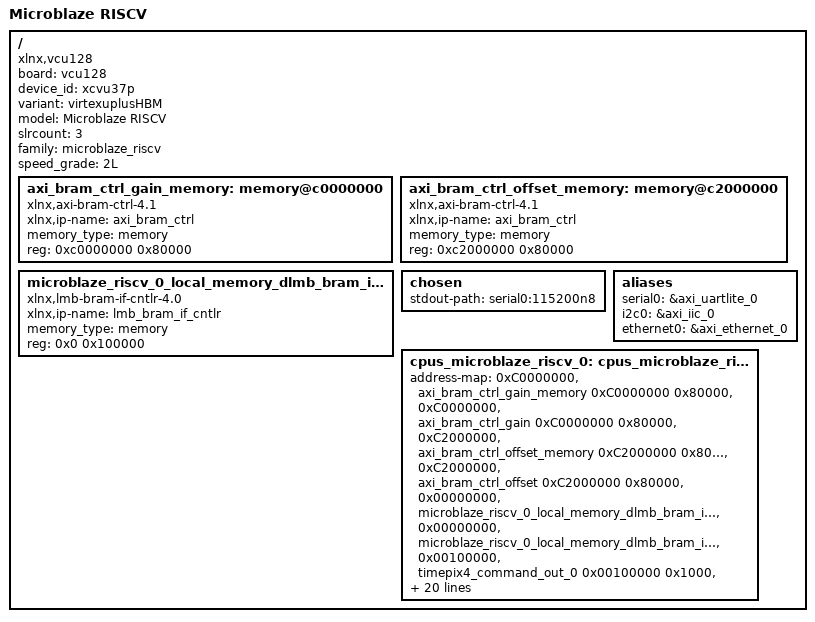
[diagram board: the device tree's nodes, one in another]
/dts-v1/;
#include "pl.dtsi"
/ {
	board = "vcu128";
	compatible = "xlnx,vcu128";
	device_id = "xcvu37p";
	#address-cells = <1>;
	variant = "virtexuplusHBM";
	model = "Microblaze RISCV";
	#size-cells = <1>;
	slrcount = <3>;
	family = "microblaze_riscv";
	speed_grade = "2L";
	axi_bram_ctrl_gain_memory: memory@c0000000 {
		compatible = "xlnx,axi-bram-ctrl-4.1";
		xlnx,ip-name = "axi_bram_ctrl";
		device_type = "memory";
		memory_type = "memory";
		reg = <0xc0000000 0x80000>;
	};
	axi_bram_ctrl_offset_memory: memory@c2000000 {
		compatible = "xlnx,axi-bram-ctrl-4.1";
		xlnx,ip-name = "axi_bram_ctrl";
		device_type = "memory";
		memory_type = "memory";
		reg = <0xc2000000 0x80000>;
	};
	microblaze_riscv_0_local_memory_dlmb_bram_if_cntlr_memory: memory@0 {
		compatible = "xlnx,lmb-bram-if-cntlr-4.0";
		xlnx,ip-name = "lmb_bram_if_cntlr";
		device_type = "memory";
		memory_type = "memory";
		reg = <0x0 0x100000>;
	};
	chosen {
		stdout-path = "serial0:115200n8";
	};
	aliases {
		serial0 = &axi_uartlite_0;
		i2c0 = &axi_iic_0;
		ethernet0 = &axi_ethernet_0;
	};
	cpus_microblaze_riscv_0: cpus_microblaze_riscv@0 {
		address-map = <0xC0000000 &axi_bram_ctrl_gain_memory 0xC0000000 0x80000>, 
			      <0xC0000000 &axi_bram_ctrl_gain 0xC0000000 0x80000>, 
			      <0xC2000000 &axi_bram_ctrl_offset_memory 0xC2000000 0x80000>, 
			      <0xC2000000 &axi_bram_ctrl_offset 0xC2000000 0x80000>, 
			      <0x00000000 &microblaze_riscv_0_local_memory_dlmb_bram_if_cntlr_memory 0x00000000 0x100000>, 
			      <0x00000000 &microblaze_riscv_0_local_memory_dlmb_bram_if_cntlr 0x00000000 0x100000>, 
			      <0x00100000 &timepix4_command_out_0 0x00100000 0x1000>, 
			      <0x00101000 &timepix_gpio_AXI_0 0x00101000 0x1000>, 
			      <0x00110000 &timepix4_sc_in_AXI_0 0x00110000 0x1000>, 
			      <0x40000000 &axi_gpio_cmac 0x40000000 0x10000>, 
			      <0x40010000 &axi_gpio_1 0x40010000 0x10000>, 
			      <0x40020000 &axi_gpio_0 0x40020000 0x10000>, 
			      <0x40030000 &axi_gpio_centroid 0x40030000 0x10000>, 
			      <0x40600000 &axi_uartlite_0 0x40600000 0x10000>, 
			      <0x40800000 &axi_iic_0 0x40800000 0x10000>, 
			      <0x40c00000 &axi_ethernet_0 0x40c00000 0x40000>, 
			      <0x41200000 &microblaze_riscv_0_axi_intc 0x41200000 0x10000>, 
			      <0x41c00000 &axi_timer_0 0x41c00000 0x10000>, 
			      <0x44a00000 &axi_ethernet_0_fifo 0x44a00000 0x10000>;
		#ranges-address-cells = <0x1>;
		#ranges-size-cells = <0x1>;
	};
};
